# PIC32CX2051BZ66048 device description
Architecture: CORTEX-M4; Family: PIC32CX; Series: PIC32CXBZ66
Registers are 32-bit, read-write, reset 0x0 unless marked. A register's access mark holds for its fields unless they carry their own. Offsets are from the block's base; [hi:lo] are bit positions; {n}, {i} and the like mark numbered series; 'fields as' and 'values as' point back to an identical list.

## ADCHS — 12-bit Analog to Digital Converter
Instances: ADCHS 0x44001500
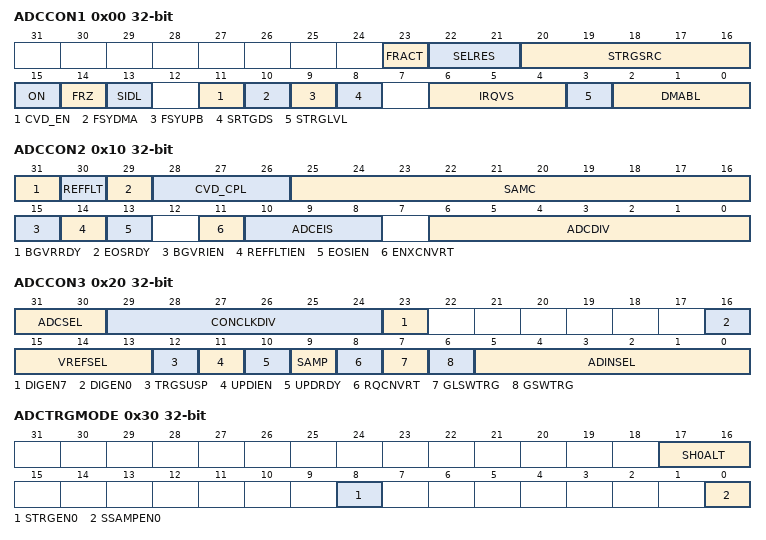
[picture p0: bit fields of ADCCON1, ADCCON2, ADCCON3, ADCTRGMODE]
0x00 ADCCON1
  [23] FRACT — Fractional Data Output Format bit
    1=FRAC (Fractional); 0=INT (Integer)
  [22:21] SELRES — Shared ADC7 Resolution bits
    3=12_BITS (12 bits (default)); 2=10_BITS; 1=8_BITS; 0=6_BITS
  [20:16] STRGSRC — Scan Trigger Source Select bits
    31=EXT_TRIG_VAL (External trigger for validation); {v}=EVSYS_{v+31} (ADC_TRIG_{v}) (v=5..16); 4=INT0; 2=SW_LVL (Software level trigger); 1=SW_EDGE (Software edge trigger); 0=NONE (No Trigger)
  [15] ON — ADC Module Enable bit
    1=ENABLED (ADC module is enabled); 0=DISABLED (ADC module is disabled)
  [14] FRZ — Freeze in debug mode
  [13] SIDL — Stop in Idle Mode bit
    1=DISCONTINUE (Discontinue module operation when device enters Idle mode); 0=CONTINUE (Continue module operation in Idle mode)
  [11] CVD_EN — CVD Enable bit
  [10] FSYDMA — Fast Synchronous DMA System Clock to the ADC control clock
  [9] FSYUPB — Fast Synchronous UPB Clock to the ADC control clock
  [8] SRTGDS — Scan Re-trigger Disable
  [6:4] IRQVS — Interrupt Vector Shift bits
    {v}=SHL_{v} (Shift x left {v} bit position) (v=0..7)
  [3] STRGLVL — Scan Trigger High Level/Positive Edge Sensitivity bit
    1=SCTRIG_HIGH (Scan trigger is high level sensitive. Once STRIG mode is selected the scan trigger will continue for all selected analog inputs); 0=SCTRIG_POSEDGE (Scan trigger is positive edge sensitive. Once STRIG mode is selected only a single scan trigger will be generated which will complete the scan of all selected analog inputs. (TRGSRCx in the ADCTRGx register))
  [2:0] DMABL — DMA to System RAM Buffer Length Size bits
    7=128_DMABL (Allocates 128 locations in system memory to each analog input); 6=64_DMABL (Allocates 64 locations in system memory to each analog input); 5=32_DMABL (Allocates 32 locations in system memory to each analog input); 4=16_DMABL (Allocates 16 locations in system memory to each analog input); 3=8_DMABL (Allocates 8 locations in system memory to each analog input); 2=4_DMABL (Allocates 4 locations in system memory to each analog input); 1=2_DMABL (Allocates 2 locations in system memory to each analog input); 0=1_DMABL (Allocates 1 location in system memory to each analog input)
0x04 ADCCON1CLR — Bit clear register
0x08 ADCCON1SET — Bit set register
0x0C ADCCON1INV — Bit invert register
0x10 ADCCON2
  [31] BGVRRDY — Band Gap Voltage/ADC Reference Voltage Status bit
    1=VREF_RDY (Both band gap voltage and ADC reference voltages (Vref) are ready); 0=VREF_NOTRDY (Either or both band gap voltage and ADC reference voltages (Vref) are not ready)
  [30] REFFLT — Band Gap/ Vref / AVdd BOR Fault Status bit
    1=BG_VREF_FLT (Fault in band gap or the Vref voltage while the ON bit (ADCCON1) was set. Most likely a band gap or Vref fault will be caused by a BOR of the analog Vdd supply.); 0=BG_VREF_OK (Band gap and Vref voltage are working properly)
  [29] EOSRDY — End of Scan Interrupt Status bit
    1=SCAN_COMPLETE (All analog inputs are considered for scanning through the scan trigger (all analog inputs specified in the ADCCSS1 and ADCCSS2 registers) have completed scanning); 0=SCAN_NOT_COMPLETE (Scanning has not completed)
  [28:26] CVD_CPL — CVD Partly Line Capacitor Setting bits
  [25:16] SAMC — Sample Time for the Shared ADC bits
  [15] BGVRIEN — Band Gap/ Vref Voltage Ready Interrupt Enable bit
    1=BGVRDDY_INT (Interrupt will be generated when the BGVRDDY bit is set); 0=NOBGVRDDY_INT (No interrupt is generated when the BGVRRDY bit is set)
  [14] REFFLTIEN — Band Gap/ Vref Voltage Fault Interrupt Enable bit
    1=REFFLT_INT (Interrupt will be generated when the REFFLT bit is set); 0=NOREFFLT_INT (No interrupt is generated when the REFFLT bit is set)
  [13] EOSIEN — End of Scan Interrupt Enable bit
    1=EOSRDY_INT (Interrupt will be generated when EOSRDY bit is set); 0=NOEOSRDY_INT (No interrupt is generated when the EOSRDY bit is set)
  [11] ENXCNVRT — Enable External Conversion Request Interface
  [10:8] ADCEIS — Shared ADC Early Interrupt Select bits
    {v}={v+1}CLKS_EARLY (The data ready interrupt is generated {v+1} ADC clocks prior to end of conversion) (v=2..7); 1=2CLKS_EARLY (The data ready interrupt is generated 2 ADC module clocks prior to end of conversion); 0=1CLKS_EARLY (The data ready interrupt is generated 1 ADC module clock prior to end of conversion)
  [6:0] ADCDIV — Shared ADC Clock Divider bits
0x14 ADCCON2CLR — Bit clear register
0x18 ADCCON2SET — Bit set register
0x1C ADCCON2INV — Bit invert register
0x20 ADCCON3
  [31:30] ADCSEL — Analog-to-Digital Clock Source bits
    3=SYSCLK; 2=REFCLK3; 1=FRC; 0=PBCLK1
  [29:24] CONCLKDIV — Analog-to-Digital Control Clock Divider bits
  [23] DIGEN7 — Shared ADC (ADC7) Digital Enable bit
  [16] DIGEN0 — ADC0 Digital Enable bit
    1=ADC0_DIG_EN (ADC0 is digital enabled (required for active operation)); 0=ADC0_DIG_DIS (ADC0 is digital disabled (power-saving mode))
  [15:13] VREFSEL — Voltage Reference Input Selection bits
    0=AVDD_AVSS (ADC VREFH is AVDD, ADC VREFL is AVSS)
  [12] TRGSUSP — Trigger Suspend bit
    1=TRIG_BLOCKED (Triggers are blocked from starting a new analog-to-digital conversion); 0=TRIG_NOT_BLOCKED (Triggers are not blocked)
  [11] UPDIEN — Update Ready Interrupt Enable bit
    1=INT_ON_UPDATE_RDY (Interrupt will be generated when the UPDRDY bit is set by hardware); 0=NO_INT_ON_UPDATE_RDY (No interrupt is generated)
  [10] UPDRDY — ADC Update Ready Status bit
    1=UPDATE_RDY (ADC SFRs can be updated); 0=UPDATE_NOT_RDY (ADC SFRs cannot be updated)
  [9] SAMP — Shared ADC7 Analog Input Sampling Enable bit
    1=SAMPLE (The ADC S&H amplifier is sampling); 0=HOLD (The ADC S&H amplifier is holding)
  [8] RQCNVRT — Individual ADC Input Conversion Request bit
    1=IND_TRIGGER (Trigger the conversion of the selected ADC input as specified by the ADINSEL bits); 0=NO_TRIGGER (Do not trigger the conversion)
  [7] GLSWTRG — Global Level Software Trigger bit
    1=GLSWTRG (Trigger conversion for ADC inputs that have selected the GLSWTRG bit as the trigger signal); 0=NO_GLSWTRG (Do not trigger an analog-to-digital conversion)
  [6] GSWTRG — Global Software Trigger bit
    1=GSWTRG (Trigger conversion for ADC inputs that have selected the GSWTRG bit as either through the associated TRGSRC bits in the ADCTRGx registers or through the STRGSRC<4:0> bits in the ADCCON1 register the trigger signal); 0=NO_GSWTRG (Do not trigger an analog-to-digital conversion)
  [5:0] ADINSEL — Analog Input Select bits
    22=TMP_SENSE (CTMU Temperature Sensor (internal AN22)); 21=VBATDIV2_SENSE (VBAT/2 (internal AN21)); 20=1P2V_SENSE (IVref 1.2V (internal AN20)); 19=BGREF (BandGap Reference (internal AN19)); {v}=AN{v} (v=0..8)
0x24 ADCCON3CLR — Bit clear register
0x28 ADCCON3SET — Bit set register
0x2C ADCCON3INV — Bit invert register
0x30 ADCTRGMODE reset not defined — ADC Triggering Mode for Dedicated ADC Register
  [17:16] SH0ALT — ADC0 Analog Input Select bit
    2=ANB0; 1=ANA0; 0=AN0
  [8] STRGEN0 — ADC0 Presynchronized Triggers bit
  [0] SSAMPEN0 — ADC0 Synchronous Sampling bit
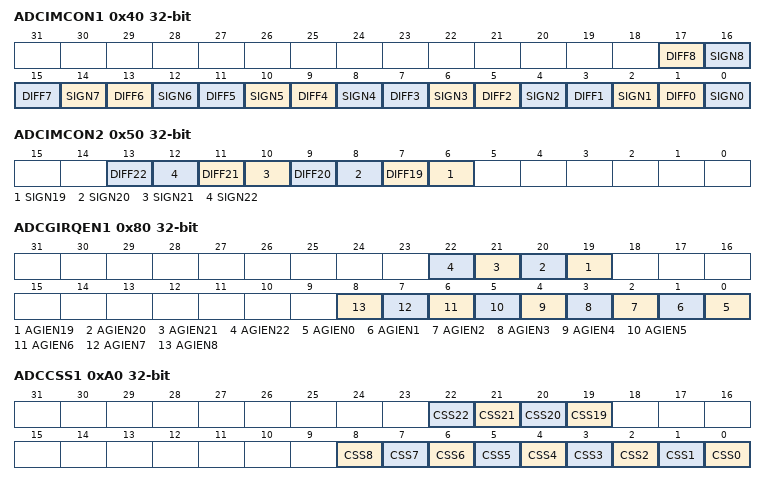
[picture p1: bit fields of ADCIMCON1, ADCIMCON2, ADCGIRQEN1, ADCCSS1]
0x40 ADCIMCON1
  [2n+1] DIFF{n} (n=0..8) — AN{n} Mode bit
    1=DIFF (Selects AN{n} differential input pair as AN{n}+ and ANN0-); 0=SINGLE (AN{n} is using Single-ended mode)
  [2n] SIGN{n} (n=0..8) — AN{n} Signed Data Mode bit
    1=SIGNED (AN{n} is using Signed Data mode); 0=UNSIGNED (AN{n} is using Unsigned Data mode)
0x44 ADCIMOD1CLR — Bit clear register
0x48 ADCIMOD1SET — Bit set register
0x4C ADCIMOD1INV — Bit invert register
0x50 ADCIMCON2
  [2n-31] DIFF{n} (n=19..22) — AN{n} Mode bit
    values as ADCIMCON1.DIFF0
  [2n-32] SIGN{n} (n=19..22) — AN{n} Signed Data Mode bit
    values as ADCIMCON1.SIGN0
0x80 ADCGIRQEN1
  [all] fields
    1=ENABLED (Interrupts are enabled for the selected analog input. The interrupt is generated after the converted data is ready (indicated by the AIRDYx bit of the ADCDSTAT1 register)); 0=DISABLED (Interrupts are disabled)
  [n] AGIEN{n} (n=19..22) — ADC Global Interrupt Enable bit {n}
  [n] AGIEN{n} (n=0..8) — ADC Global Interrupt Enable bit {n}
0x84 ADCGIRQEN1CLR — Bit clear register
0x88 ADCGIRQEN1SET — Bit set register
0x8C ADCGIRQEN1INV — Bit invert register
0xA0 ADCCSS1
  [n] CSS{n} (n=19..22) — Analog Common Scan Select bits
    1=SEL_AN{n} (Select ANx for input scan (i.e.ANx = CSSx and scan is sequential starting with the lowest to highest enabled CSSx analog input pin)); 0=SKIP_AN{n} (Skip ANx for input scan)
  [n] CSS{n} (n=0..8) — Analog Common Scan Select bits
    values as CSS19
0xA4 ADCCSS1CLR — Bit clear register
0xA8 ADCCSS1SET — Bit set register
0xAC ADCCSS1INV — Bit invert register
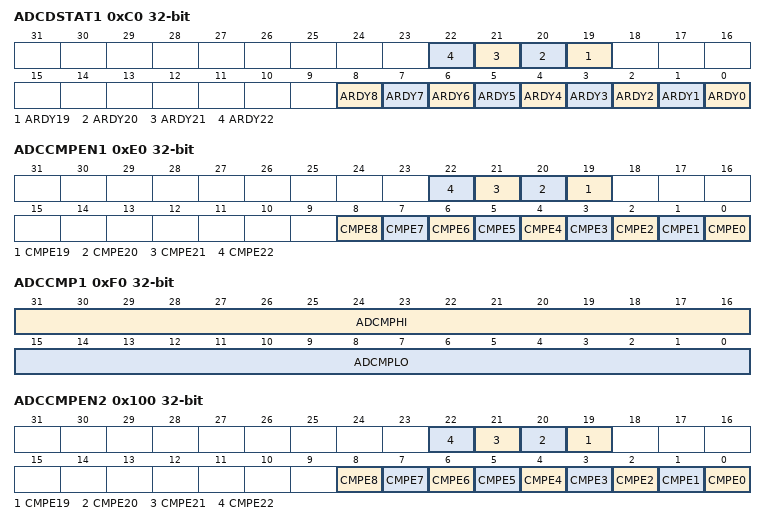
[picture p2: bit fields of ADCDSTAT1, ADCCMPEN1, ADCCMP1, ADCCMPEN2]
0xC0 ADCDSTAT1
  [n] ARDY{n} (n=19..22), [n] ARDY{n} (n=0..8)
0xC4 ADCDSTAT1CLR — Bit clear register
0xC8 ADCDSTAT1SET — Bit set register
0xCC ADCDSTAT1INV — Bit invert register
0xE0 ADCCMPEN1
  [n] CMPE{n} (n=19..22), [n] CMPE{n} (n=0..8)
0xE4 ADCCMPEN0CLR — Bit clear register
0xE8 ADCCMPEN0SET — Bit set register
0xEC ADCCMPEN0INV — Bit invert register
0xF0 ADCCMP1
  [31:16] ADCMPHI, [15:0] ADCMPLO
0xF4 ADCCMP0CLR — Bit clear register
0xF8 ADCCMP0SET — Bit set register
0xFC ADCCMP0INV — Bit invert register
0x100 ADCCMPEN2
  [n] CMPE{n} (n=19..22), [n] CMPE{n} (n=0..8)
0x104 ADCCMPEN1CLR — Bit clear register
0x108 ADCCMPEN1SET — Bit set register
0x10C ADCCMPEN1INV — Bit invert register
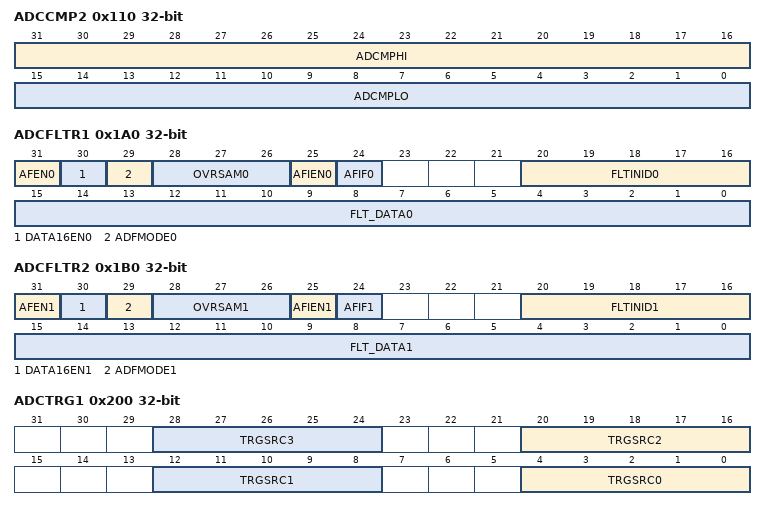
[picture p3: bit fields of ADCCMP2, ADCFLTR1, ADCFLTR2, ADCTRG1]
0x110 ADCCMP2
  [31:16] ADCMPHI, [15:0] ADCMPLO
0x114 ADDCMP1CLR — Bit clear register
0x118 ADDCMP1SET — Bit set register
0x11C ADDCMP1INV — Bit invert register
0x1A0 ADCFLTR1
  [31] AFEN0, [30] DATA16EN0, [29] ADFMODE0, [28:26] OVRSAM0, [25] AFIEN0, [24] AFIF0, [20:16] FLTINID0, [15:0] FLT_DATA0
0x1A4 ADCFLTR0CLR — Bit clear register
0x1A8 ADCFLTR0SET — Bit set register
0x1AC ADCFLTR0INV — Bit invert register
0x1B0 ADCFLTR2
  [31] AFEN1, [30] DATA16EN1, [29] ADFMODE1, [28:26] OVRSAM1, [25] AFIEN1, [24] AFIF1, [20:16] FLTINID1, [15:0] FLT_DATA1
0x1B4 ADCFLTR1CLR — Bit clear register
0x1B8 ADCFLTR1SET — Bit set register
0x1BC ADCFLTR1INV — Bit invert register
0x200 ADCTRG1 — ADC Trigger Source 1 Register
  [all] fields
    {v}=EVSYS_{v+37} (ADC_TRIG_{v}) (v=5..16); 4=INT0; 3=SCAN_TRIG (Scan trigger); 2=SW_LVL (Software level trigger); 1=SW_EDGE (Software edge trigger); 0=NONE (No Trigger)
  [8n+4:8n] TRGSRC{n} (n=0..3) — Trigger Source for Conversion of ADC{n} Module Select bits
0x204 ADCTRG1CLR — Bit clear register
0x208 ADCTRG1SET — Bit set register
0x20C ADCTRG1INV — Bit invert register
0x210 ADCTRG2 — ADC Trigger Source 2 Register
  [all] fields
    values as the fields of ADCTRG1
  [12:8] TRGSRC5 — Trigger Source for Conversion of ADC5 Module Select bits
  [12:8] TRGSRC7 — Trigger Source for Conversion of ADC7 Module Select bits
  [4:0] TRGSRC4 — Trigger Source for Conversion of ADC4 Module Select bits
  [4:0] TRGSRC6 — Trigger Source for Conversion of ADC6 Module Select bits
0x214 ADTRG2CLR — Bit clear register
0x218 ADTRG2SET — Bit set register
0x21C ADTRG2INV — Bit invert register
0x224 ADTRG3CLR — Bit clear register
0x228 ADTRG3SET — Bit set register
0x22C ADTRG3INV — Bit invert register
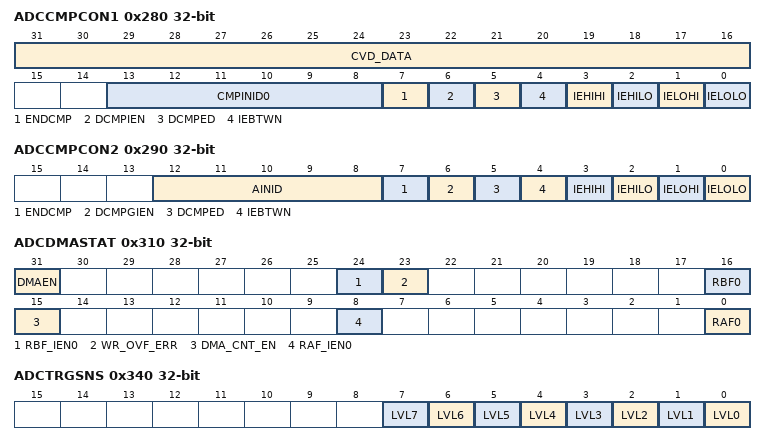
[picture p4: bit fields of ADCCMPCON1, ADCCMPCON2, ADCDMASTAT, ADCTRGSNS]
0x280 ADCCMPCON1
  [31:16] CVD_DATA, [13:8] CMPINID0, [7] ENDCMP, [6] DCMPIEN, [5] DCMPED, [4] IEBTWN, [3] IEHIHI, [2] IEHILO, [1] IELOHI, [0] IELOLO
0x284 ADCCMPCON1CLR — Bit clear register
0x288 ADCCMPCON1SET — Bit set register
0x28C ADCCMPCON1INV — Bit invert register
0x290 ADCCMPCON2
  [12:8] AINID, [7] ENDCMP, [6] DCMPGIEN, [5] DCMPED, [4] IEBTWN, [3] IEHIHI, [2] IEHILO, [1] IELOHI, [0] IELOLO
0x294 ADCMPCON2CLR — Bit clear register
0x298 ADCMPCON2SET — Bit set register
0x29C ADCMPCON2INV — Bit invert register
0x2E4 ADCFSTATCLR — Bit clear register
0x2E8 ADCFSTATSET — Bit set register
0x2EC ADCFSTATINV — Bit invert register
0x2F4 ADCFIFOCLR — Bit clear register
0x2F8 ADCFIFOSET — Bit set register
0x2FC ADCFIFOINV — Bit invert register
0x300 ADCBASE
  [15:0] ADCBASE
0x304 ADCBASECLR — Bit clear register
0x308 ADCBASESET — Bit set register
0x30C ADCBASEINV — Bit invert register
0x310 ADCDMASTAT
  [31] DMAEN, [24] RBF_IEN0, [23] WR_OVF_ERR, [16] RBF0, [15] DMA_CNT_EN, [8] RAF_IEN0, [0] RAF0
0x314 ADCDMASTATCLR — Bit clear register
0x318 ADCDMASTATSET — Bit set register
0x31C ADCDMASTATINV — Bit invert register
0x320 ADCCNTB
0x324 ADCCNTBCLR — Bit clear register
0x328 ADCCNTBSET — Bit set register
0x32C ADCCNTBINV — Bit invert register
0x330 ADCDMAB
  [31:0] ADDMAB
0x334 ADCDMABCLR — Bit clear register
0x338 ADCDMABSET — Bit set register
0x33C ADCDMABINV — Bit invert register
0x340 ADCTRGSNS
  [n] LVL{n} (n=0..7)
0x344 ADCTRGSNSCLR — Bit clear register
0x348 ADCTRGSNSSET — Bit set register
0x34C ADCTRGSNSINV — Bit invert register
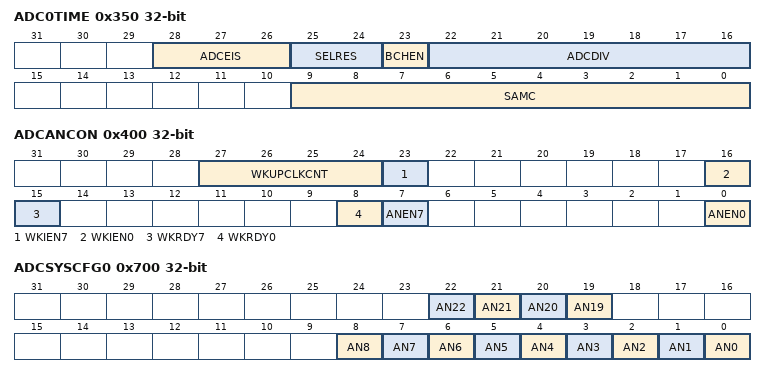
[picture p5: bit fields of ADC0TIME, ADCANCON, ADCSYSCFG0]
0x350 ADC0TIME reset not defined — Dedicated High-Speed ADC Timing Register ('x' = 0)
  [28:26] ADCEIS — ADCx Early Interrupt Select bits
  [25:24] SELRES — ADCx Resolution Select bits
    3=12_BITS; 2=10_BITS; 1=8_BITS; 0=6_BITS
  [23] BCHEN — Buffer Channel Enable bit
  [22:16] ADCDIV — ADCx Clock Divisor bits
  [9:0] SAMC — ADCx Sample Time bits
0x354 ADC0TIMECLR — Bit clear register
0x358 ADC0TIMESET — Bit set register
0x35C ADC0TIMEINV — Bit invert register
0x3E4 ADCEISTAT1CLR — Bit clear register
0x3E8 ADCEISTAT1SET — Bit set register
0x3EC ADCEISTAT1INV — Bit invert register
0x400 ADCANCON
  [27:24] WKUPCLKCNT, [23] WKIEN7, [16] WKIEN0, [15] WKRDY7, [8] WKRDY0, [7] ANEN7, [0] ANEN0
0x404 ADCANLCTLCLR — Bit clear register
0x408 ADCANLCTLSET — Bit set register
0x40C ADCANLCTLINV — Bit invert register
0x670 ADC7CFG
0x674 ADCFGSHRCLR — Bit clear register
0x678 ADCFGSHRSET — Bit set register
0x67C ADCFGSHRINV — Bit invert register
0x684 ADCSVCONCLR — Bit clear register
0x688 ADCSVCONSET — Bit set register
0x68C ADCSVCONINV — Bit invert register
0x700 ADCSYSCFG0
  [n] AN{n} (n=19..22), [n] AN{n} (n=0..8)
0x704 ADCSYSCFG0CLR — Bit clear register
0x708 ADCSYSCFG0SET — Bit set register
0x70C ADCSYSCFG0INV — Bit invert register
{0xA00+0x10*i} ADCDATA{i} ro (i=0..6)
  [31:0] DATA
0xA70 ADCDATA7
  [31:0] DATA
0xA80 ADCDATA8 ro
  [31:0] DATA
{0xA00+0x10*i} ADCDATA{i} ro (i=19..22)
  [31:0] DATA
Value list ADCCON1__FSPBCLKEN: 1=ENABLED (Fast synchronous peripheral clock to ADC control clock is enabled); 0=DISABLED (Fast synchronous peripheral clock to ADC control clock is disabled)
Value list ADCCON1__FSSCLKEN: 1=ENABLED (Fast synchronous system clock to ADC control clock is enabled); 0=DISABLED (Fast synchronous system clock to ADC control clock is disabled)
Value list ADCCON1__AICPMPEN: 1=ENABLED (Analog input charge pump is enabled); 0=DISABLED (Analog input charge pump is disabled (default))
